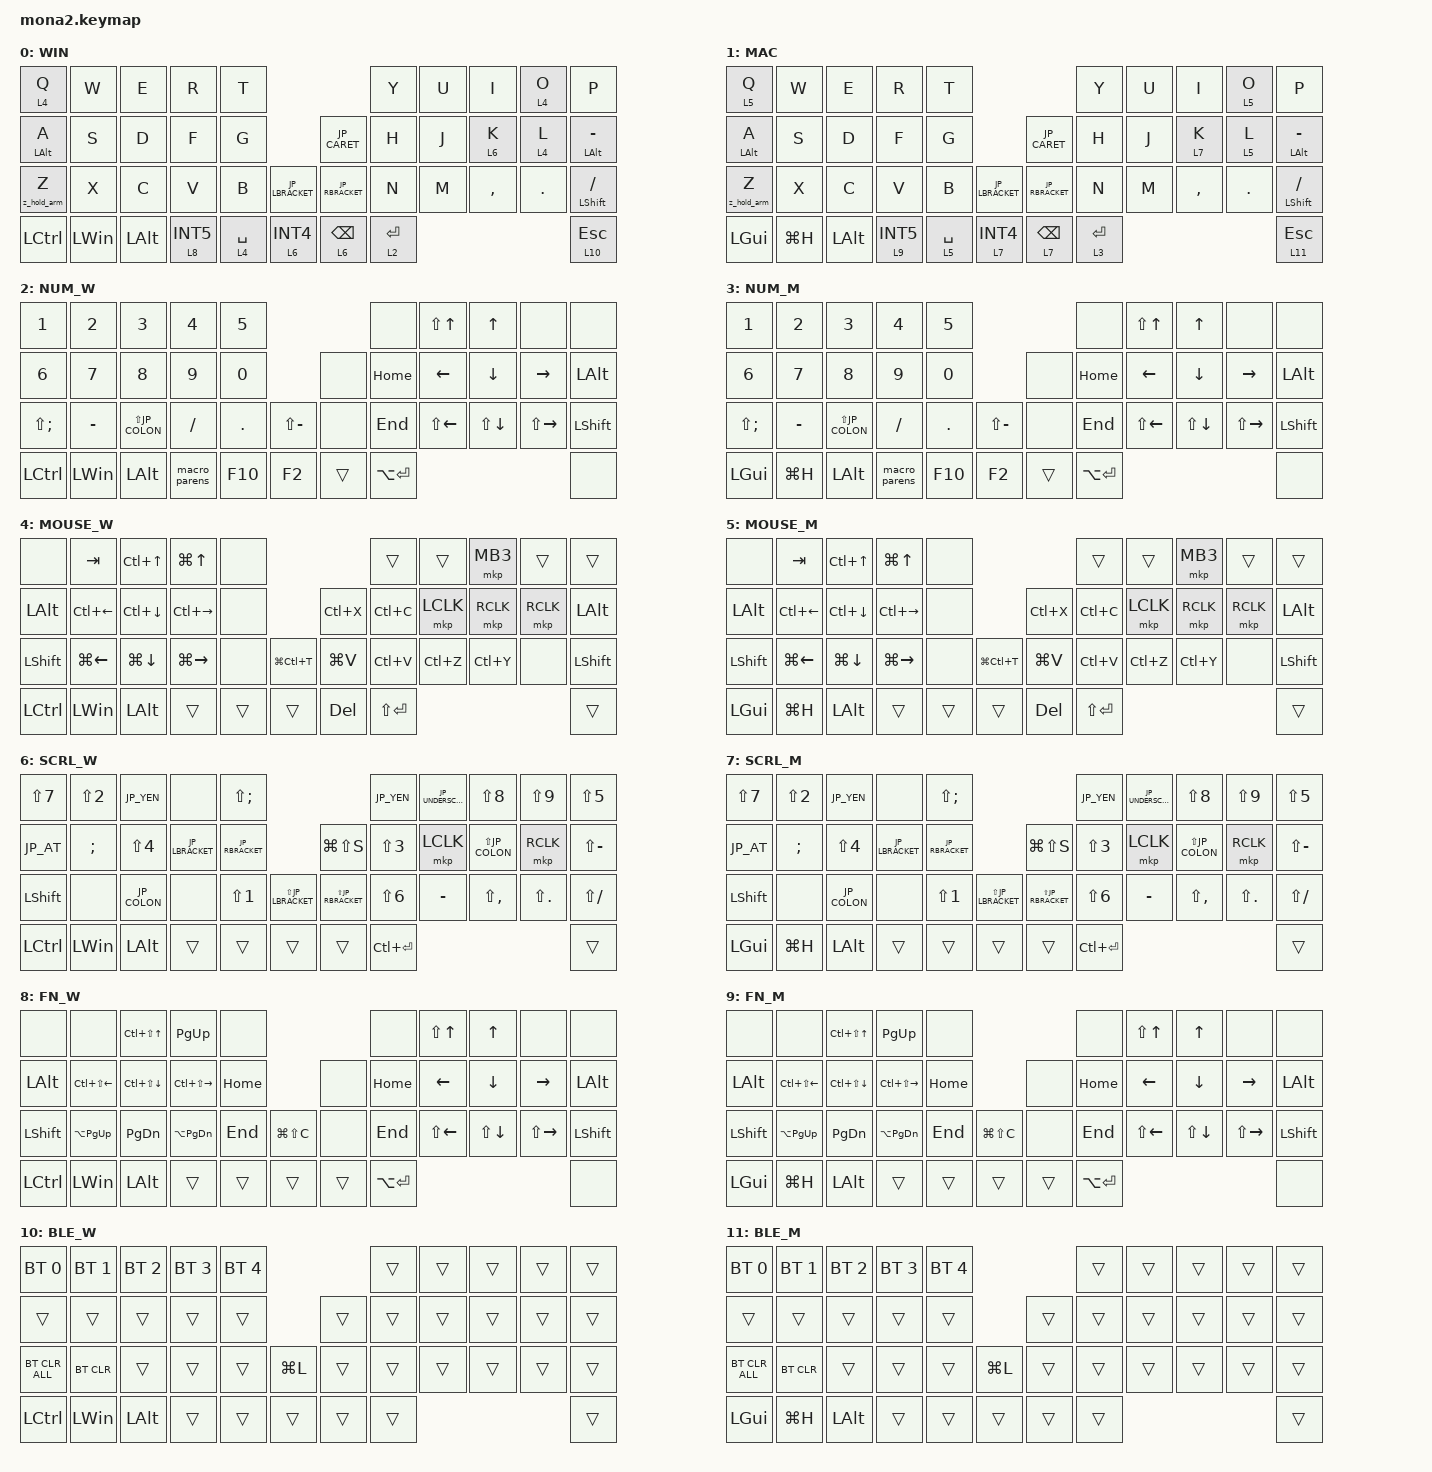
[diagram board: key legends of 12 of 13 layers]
#include <input/processors.dtsi>
#include <dt-bindings/zmk/input_transform.h>
#include <zephyr/dt-bindings/input/input-event-codes.h>
#include <behaviors.dtsi>

&sl {
    release-after-ms = <300>;
};
#include <behaviors/runtime-sensor-rotate.dtsi>
#include <dt-bindings/zmk/bt.h>
#include <dt-bindings/zmk/keys.h>
#include <dt-bindings/zmk/outputs.h>
#include <dt-bindings/zmk/pointing.h>

// JIS キーボード配列用の物理キーコード (roBa の定義に合わせる)
#define JP_AT           LBKT
#define JP_CARET        EQUAL
#define JP_YEN          INT3
#define JP_PIPE         LS(INT3)
#define JP_COLON        SQT
#define JP_LBRACKET     RBKT
#define JP_RBRACKET     NUHS
#define JP_UNDERSCORE   LS(INT1)
#define JP_BACKSLASH    INT1
#define JP_DQUOTE       LS(N2)
#define JP_AMPERSAND    LS(N6)
#define JP_QUOTE        LS(N7)
#define JP_LPAREN       LS(N8)
#define JP_RPAREN       LS(N9)
#define JP_EQUAL        LS(MINUS)
#define JP_PLUS         LS(SEMI)
#define JP_ASTERISK     LS(SQT)
#define JP_TILD         LS(EQUAL)
#define JP_GRAVE        LS(LBKT)
#define JP_LBRACE       LS(RBKT)
#define JP_RBRACE       LS(NUHS)


/* ZMK 側で 10 が定義済みなので警告回避のため一旦 undef */
#undef ZMK_POINTING_DEFAULT_SCRL_VAL
#define ZMK_POINTING_DEFAULT_SCRL_VAL 100

&mt {
flavor = "balanced";
quick-tap-ms = <0>;
};

&lt {
quick-tap-ms = <200>;
flavor = "balanced";
};

&msc {
delay-ms = <0>;
time-to-max-speed-ms = <0>;
acceleration-exponent = <0>;
};

/ {
combos {
compatible = "zmk,combos";

layer4_ESC {
bindings = <&lt 4 ESC>;
key-positions = <39 38>;
};

tab {
bindings = <&kp TAB>;
key-positions = <11 12>;
};
};

macros {
        // roBaと同じ: 長押し中はShift、離した直後だけ次のZを大文字にする。
        z_hold_arm: z_hold_arm {
            compatible = "zmk,behavior-macro";
            #binding-cells = <0>;
            wait-ms = <0>;
            tap-ms = <10>;
            bindings =
                <&macro_press &kp LSHFT>
                , <&macro_pause_for_release>
                , <&macro_release &kp LSHFT>
                , <&macro_tap &sl 12>;
        };

            macro_parens: macro_parens {
            compatible = "zmk,behavior-macro";
            #binding-cells = <0>;
            wait-ms = <20>; // キー入力間の待機時間
            tap-ms = <20>;  // キーを押している時間
            bindings
                = <&kp LS(N8)>    // 「(」を入力
                , <&kp LS(N9)>    // 「)」を入力
                , <&kp LEFT>;  // 左矢印「←」を入力してカーソルを戻す
        };
to_layer_0: to_layer_0 {
compatible = "zmk,behavior-macro-one-param";
#binding-cells = <1>;
bindings = <&to 0 &macro_param_1to1 &kp MACRO_PLACEHOLDER>;
label = "TO_LAYER_0";
};

BT0: BT0 {
compatible = "zmk,behavior-macro";
#binding-cells = <0>;
bindings =
<&tog_off 0 &tog_off 1>,
<&macro_wait_time 200>,
<&bt BT_SEL 0>,
<&macro_wait_time 500>,
<&tog_on 0>;

label = "BT0";
};

BT1: BT1 {
compatible = "zmk,behavior-macro";
#binding-cells = <0>;
bindings =
<&tog_off 0 &tog_off 1>,
<&macro_wait_time 200>,
<&bt BT_SEL 1>,
<&macro_wait_time 500>,
<&tog_on 1>;

label = "BT1";
};

screenshot: screenshot {
compatible = "zmk,behavior-macro";
#binding-cells = <0>;
bindings =
<&macro_press>,
<&kp LEFT_GUI &kp RSHIFT>,
<&macro_wait_time 20>,
<&macro_tap>,
<&kp S>,
<&macro_release>,
<&kp LEFT_GUI &kp RSHIFT>;

label = "SCREENSHOT";
};

henkan: henkan {
compatible = "zmk,behavior-macro";
#binding-cells = <0>;
bindings =
<&macro_press>,
<&kp LEFT_ALT>,
<&macro_wait_time 20>,
<&macro_tap>,
<&kp GRAVE>,
<&macro_release>,
<&kp LEFT_ALT>;

label = "HENKAN";
};
};

behaviors {
        // A専用: 単独保持時のAlt確定を200msから320msへ遅らせる。
        // 他のキーとの同時打鍵では元のtap-preferredを維持する。
        a_alt_slow: a_alt_slow {
            compatible = "zmk,behavior-hold-tap";
            #binding-cells = <2>;
            bindings = <&kp>, <&kp>;
            flavor = "tap-preferred";
            tapping-term-ms = <320>;
            quick-tap-ms = <150>;
            require-prior-idle-ms = <125>;
        };

        // 右Shift専用: 左Zと同じ170ms。通常のスラッシュ入力はタップ優先。
        slash_shift_fast: slash_shift_fast {
            compatible = "zmk,behavior-hold-tap";
            #binding-cells = <2>;
            bindings = <&kp>, <&kp>;
            flavor = "tap-preferred";
            tapping-term-ms = <170>;
            quick-tap-ms = <0>;
            require-prior-idle-ms = <125>;
        };

        // 高速タイピング用のMod-Tap設定（Home Row Mods用）
        mt_tap: mod_tap_preferred {
            compatible = "zmk,behavior-hold-tap";
            #binding-cells = <2>;
            flavor = "tap-preferred";      // ★重要：他のキーと重なってもTap（文字）を優先する
            tapping-term-ms = <200>;       // 長押しの判定時間（好みで調整）
            quick-tap-ms = <150>;          // 連続タップで文字をリピートさせる
            require-prior-idle-ms = <125>; // ★超重要：直前に別のキーを打っていたら、強制的にTapにする
            bindings = <&kp>, <&kp>;
        };
        
        // KとL専用の遅いLayer-Tap
        lt_slow: layer_tap_slow {
            compatible = "zmk,behavior-hold-tap";
            #binding-cells = <2>;
            flavor = "tap-preferred"; // 短く押した時は確実にキー入力を優先
            tapping-term-ms = <250>;  // ★ここを好みの長さに設定（デフォルトは200）
            quick-tap-ms = <200>;     // 連続タップ時のレイヤー暴発防止
            require-prior-idle-ms = <125>; // ★これを追加：直前に別のキー入力があれば絶対にTap(文字)にする
            bindings = <&mo>, <&kp>;  // 長押しでレイヤー(&mo)、短押しでキー(&kp)
            
            display-name = "Layer Tap Slow";
        };

        // ダブルタップ＆ホールドで連続バックスペースになるLayer-Tap
        lt_bspc: layer_tap_backspace {
            compatible = "zmk,behavior-hold-tap";
            #binding-cells = <2>;
            flavor = "tap-preferred";
            tapping-term-ms = <200>; // 通常の長押し（Hold）判定時間
            quick-tap-ms = <200>;    // ★ここがダブルタップリピートの受付時間です
            bindings = <&mo>, <&kp>; // ※もしMod-Tapとして使う場合は <&kp>, <&kp> にしてください
        };

lt_to_layer_0: lt_to_layer_0 {
compatible = "zmk,behavior-hold-tap";
label = "LAYER_TAP_TO_0";
bindings = <&mo>, <&to_layer_0>;

#binding-cells = <2>;
tapping-term-ms = <200>;
};

tp_repeat_mo1: tp_repeat_mo1 {
compatible = "zmk,behavior-hold-tap";
label = "TP_REPEAT_MO1";
bindings = <&mo>, <&key_repeat>;

#binding-cells = <2>;
tapping-term-ms = <200>;
};

// エンコーダ用 runtime-configurable sensor rotate
// デフォルトはスクロール (cw=SCRL_DOWN, ccw=SCRL_UP)
// DYA Studio Web UI から レイヤーごとに cw/ccw の binding を
// kp C_VOL_UP/DN や kp LEFT/RIGHT などへ動的変更可能
rsr_default: rsr_default {
compatible = "zmk,behavior-runtime-sensor-rotate";
#sensor-binding-cells = <0>;
tap-ms = <16>;
cw-binding = <&msc SCRL_UP>;
ccw-binding = <&msc SCRL_DOWN>;
};

tog_on: toggle_layer_on_only {
compatible = "zmk,behavior-toggle-layer";
#binding-cells = <1>;
display-name = "Toggle Layer On";
toggle-mode = "on";
};

tog_off: toggle_layer_off_only {
compatible = "zmk,behavior-toggle-layer";
#binding-cells = <1>;
display-name = "Toggle Layer Off";
toggle-mode = "off";
};

// Hold-Tapは外側に置き、他キー押下で即座にShiftを優先確定
z_shift: z_shift {
    compatible = "zmk,behavior-hold-tap";
    label = "Z_SHIFT";
    #binding-cells = <2>;
    bindings = <&z_hold_arm>, <&kp>;
    flavor = "tap-preferred";
    tapping-term-ms = <170>;
    require-prior-idle-ms = <125>;
    quick-tap-ms = <0>;
};
};

keymap {
compatible = "zmk,keymap";

win_layer {
display-name = "WIN";
bindings = <
&lt_slow 4 Q             &kp W         &kp E    &kp R          &kp T                                                          &kp Y        &kp U  &kp I      &lt_slow 4 O    &kp P
&a_alt_slow LALT A           &kp S         &kp D    &kp F          &kp G                                  &kp JP_CARET                 &kp H        &kp J  &lt_slow 6 K      &lt_slow 4 L    &a_alt_slow LALT MINUS
&z_shift 0 Z          &kp X         &kp C    &kp V          &kp B        &kp JP_LBRACKET                   &kp JP_RBRACKET                 &kp N        &kp M  &kp COMMA  &kp DOT  &slash_shift_fast LSHFT SLASH
&kp LCTRL         &kp LWIN      &kp LEFT_ALT  &lt 8 INT5  &lt 4 SPACE  &lt 6 INT4                &lt_bspc 6 BSPC  &lt 2 RET                                                     &lt 10 ESC
>;

sensor-bindings =
<&rsr_default>,
<&inc_dec_kp C_VOL_DN C_VOL_UP>;
};

mac_layer {
display-name = "MAC";
bindings = <
&lt_slow 5 Q             &kp W         &kp E    &kp R          &kp T                                                          &kp Y        &kp U  &kp I      &lt_slow 5 O    &kp P
&a_alt_slow LALT A           &kp S         &kp D    &kp F          &kp G                                  &kp JP_CARET                 &kp H        &kp J  &lt_slow 7 K      &lt_slow 5 L    &a_alt_slow LALT MINUS
&z_shift 0 Z          &kp X         &kp C    &kp V          &kp B        &kp JP_LBRACKET                   &kp JP_RBRACKET                 &kp N        &kp M  &kp COMMA  &kp DOT  &slash_shift_fast LSHFT SLASH
&kp LGUI         &kp LG(H)      &kp LEFT_ALT  &lt 9 INT5  &lt 5 SPACE  &lt 7 INT4                &lt_bspc 7 BSPC  &lt 3 RET                                                     &lt 11 ESC
>;

sensor-bindings =
<&rsr_default>,
<&inc_dec_kp C_VOL_DN C_VOL_UP>;
};

num_win {
display-name = "NUM_W";
bindings = <
&kp N1       &kp N2      &kp N3           &kp N4        &kp N5                                  &none         &kp LS(UP)       &kp UP            &none          &none
&kp N6       &kp N7      &kp N8           &kp N9        &kp N0                        &none     &kp HOME      &kp LEFT         &kp DOWN          &kp RIGHT      &kp LALT
&kp LS(SEMI) &kp MINUS   &kp LS(JP_COLON)    &kp FSLH      &kp DOT  &kp LS(MINUS)        &none     &kp END       &kp LS(LEFT)     &kp LS(DOWN)      &kp LS(RIGHT)  &kp LSHFT
&kp LCTRL    &kp LWIN    &kp LALT         &macro_parens &kp F10  &kp F2                         &trans        &kp LA(ENTER)                                     &none
>;

sensor-bindings = <&rsr_default>;
};

num_mac {
display-name = "NUM_M";
bindings = <
&kp N1       &kp N2      &kp N3           &kp N4        &kp N5                                  &none         &kp LS(UP)       &kp UP            &none          &none
&kp N6       &kp N7      &kp N8           &kp N9        &kp N0                        &none     &kp HOME      &kp LEFT         &kp DOWN          &kp RIGHT      &kp LALT
&kp LS(SEMI) &kp MINUS   &kp LS(JP_COLON)    &kp FSLH      &kp DOT  &kp LS(MINUS)        &none     &kp END       &kp LS(LEFT)     &kp LS(DOWN)      &kp LS(RIGHT)  &kp LSHFT
&kp LGUI    &kp LG(H)    &kp LALT         &macro_parens &kp F10  &kp F2                         &trans        &kp LA(ENTER)                                     &none
>;

sensor-bindings = <&rsr_default>;
};

mouse_win {
display-name = "MOUSE_W";
bindings = <
&none      &kp TAB        &kp LC(UP)     &kp LG(UP)     &none                                  &trans     &trans     &mkp MB3    &trans       &trans
&kp LALT   &kp LC(LEFT)   &kp LC(DOWN)   &kp LC(RIGHT)  &none                       &kp LC(X)  &kp LC(C)  &mkp LCLK  &mkp RCLK   &mkp RCLK    &kp LALT
&kp LSHFT  &kp LG(LEFT)   &kp LG(DOWN)   &kp LG(RIGHT)  &none    &kp LG(LC(T))      &kp LG(V)  &kp LC(V)  &kp LC(Z)  &kp LC(Y)   &none        &kp LSHFT
&kp LCTRL  &kp LWIN       &kp LALT       &trans         &trans   &trans             &kp DEL    &kp LS(ENTER)                                  &trans
>;

sensor-bindings = <&rsr_default>;
};

mouse_mac {
display-name = "MOUSE_M";
bindings = <
&none      &kp TAB        &kp LC(UP)     &kp LG(UP)     &none                                  &trans     &trans     &mkp MB3    &trans       &trans
&kp LALT   &kp LC(LEFT)   &kp LC(DOWN)   &kp LC(RIGHT)  &none                       &kp LC(X)  &kp LC(C)  &mkp LCLK  &mkp RCLK   &mkp RCLK    &kp LALT
&kp LSHFT  &kp LG(LEFT)   &kp LG(DOWN)   &kp LG(RIGHT)  &none    &kp LG(LC(T))      &kp LG(V)  &kp LC(V)  &kp LC(Z)  &kp LC(Y)   &none        &kp LSHFT
&kp LGUI  &kp LG(H)       &kp LALT       &trans         &trans   &trans             &kp DEL    &kp LS(ENTER)                                  &trans
>;

sensor-bindings = <&rsr_default>;
};

scroll_win {
display-name = "SCRL_W";
bindings = <
&kp LS(N7)    &kp LS(N2)    &kp JP_YEN      &none          &kp LS(SEMI)                                        &kp JP_YEN       &kp JP_UNDERSCORE &kp LS(N8)       &kp LS(N9)  &kp LS(N5)
&kp JP_AT        &kp SEMI      &kp LS(N4)  &kp JP_LBRACKET         &kp JP_RBRACKET                                 &kp LG(LS(S))       &kp LS(N3)   &mkp LCLK    &kp LS(JP_COLON)           &mkp RCLK   &kp LS(MINUS)
&kp LSHFT     &none         &kp JP_COLON      &none          &kp LS(N1)       &kp LS(JP_LBRACKET)                &kp LS(JP_RBRACKET)       &kp LS(N6)   &kp MINUS    &kp LS(COMMA)    &kp LS(DOT) &kp LS(FSLH)
&kp LCTRL     &kp LWIN      &kp LALT    &trans         &trans          &trans                 &trans       &kp LC(ENTER)                                          &trans
>;

sensor-bindings = <&rsr_default>;
};

scroll_mac {
display-name = "SCRL_M";
bindings = <
&kp LS(N7)    &kp LS(N2)    &kp JP_YEN      &none          &kp LS(SEMI)                                        &kp JP_YEN       &kp JP_UNDERSCORE &kp LS(N8)       &kp LS(N9)  &kp LS(N5)
&kp JP_AT        &kp SEMI      &kp LS(N4)  &kp JP_LBRACKET         &kp JP_RBRACKET                                 &kp LG(LS(S))       &kp LS(N3)   &mkp LCLK    &kp LS(JP_COLON)           &mkp RCLK   &kp LS(MINUS)
&kp LSHFT     &none         &kp JP_COLON      &none          &kp LS(N1)       &kp LS(JP_LBRACKET)                &kp LS(JP_RBRACKET)       &kp LS(N6)   &kp MINUS    &kp LS(COMMA)    &kp LS(DOT) &kp LS(FSLH)
&kp LGUI     &kp LG(H)      &kp LALT    &trans         &trans          &trans                 &trans       &kp LC(ENTER)                                          &trans
>;

sensor-bindings = <&rsr_default>;
};

function_win {
display-name = "FN_W";
bindings = <
&none      &none                &kp LC(LS(UP))    &kp PG_UP           &none                              &none           &kp LS(UP)       &kp UP            &none          &none
&kp LALT   &kp LC(LS(LEFT))     &kp LC(LS(DOWN))  &kp LC(LS(RIGHT))   &kp HOME                  &none    &kp HOME        &kp LEFT         &kp DOWN          &kp RIGHT      &kp LALT
&kp LSHFT  &kp LA(PG_UP)        &kp PG_DN         &kp LA(PG_DN)       &kp END   &kp LG(LS(C))   &none    &kp END         &kp LS(LEFT)     &kp LS(DOWN)      &kp LS(RIGHT)  &kp LSHFT
&kp LCTRL  &kp LWIN             &kp LALT          &trans              &trans    &trans          &trans   &kp LA(ENTER)                                                     &none
>;
};

function_mac {
display-name = "FN_M";
bindings = <
&none      &none                &kp LC(LS(UP))    &kp PG_UP           &none                              &none           &kp LS(UP)       &kp UP            &none          &none
&kp LALT   &kp LC(LS(LEFT))     &kp LC(LS(DOWN))  &kp LC(LS(RIGHT))   &kp HOME                  &none    &kp HOME        &kp LEFT         &kp DOWN          &kp RIGHT      &kp LALT
&kp LSHFT  &kp LA(PG_UP)        &kp PG_DN         &kp LA(PG_DN)       &kp END   &kp LG(LS(C))   &none    &kp END         &kp LS(LEFT)     &kp LS(DOWN)      &kp LS(RIGHT)  &kp LSHFT
&kp LGUI  &kp LG(H)             &kp LALT          &trans              &trans    &trans          &trans   &kp LA(ENTER)                                                     &none
>;
};

ble_win {
display-name = "BLE_W";
bindings = <
&bt BT_SEL 0    &bt BT_SEL 1  &bt BT_SEL 2  &bt BT_SEL 3    &bt BT_SEL 4                          &trans  &trans  &trans  &trans  &trans
&trans          &trans        &trans        &trans          &trans                        &trans  &trans  &trans  &trans  &trans  &trans
&bt BT_CLR_ALL  &bt BT_CLR    &trans        &trans          &trans          &kp LG(L)        &trans  &trans  &trans  &trans  &trans  &trans
&kp LCTRL       &kp LWIN      &kp LALT      &trans          &trans          &trans        &trans  &trans                          &trans
>;
};

ble_mac {
display-name = "BLE_M";
bindings = <
&bt BT_SEL 0    &bt BT_SEL 1  &bt BT_SEL 2  &bt BT_SEL 3    &bt BT_SEL 4                          &trans  &trans  &trans  &trans  &trans
&trans          &trans        &trans        &trans          &trans                        &trans  &trans  &trans  &trans  &trans  &trans
&bt BT_CLR_ALL  &bt BT_CLR    &trans        &trans          &trans          &kp LG(L)        &trans  &trans  &trans  &trans  &trans  &trans
&kp LGUI       &kp LG(H)      &kp LALT      &trans          &trans          &trans        &trans  &trans                          &trans
>;
};

z_next_uppercase {
    bindings = <
&trans &trans &trans &trans &trans &trans &trans &trans &trans &trans
&trans &trans &trans &trans &trans &trans &trans &trans &trans &trans &trans
&kp LS(Z) &trans &trans &trans &trans &trans &trans &trans &trans &trans &trans &trans
&trans &trans &trans &trans &trans &trans &trans &trans &trans
    >;
};

};
};
